AUTOSAR XML (schema 314)
package /ComponentType
  internal behavior Sa_MtrPos_InternalBehavior: component=Sa_MtrPos
    timing event MtrPos_Init1_InitEvent: start-on-event=MtrPos_Init1, period=0
    timing event TMT_MtrPos_Per2: start-on-event=MtrPos_Per2, period=0.002
    operation invoked event OIT_MtrPos_SCom_ReadEOLMtrCals_MtrPos_SCom_ReadEOLMtrCals: start-on-event=MtrPos_SCom_ReadEOLMtrCals, operation=MtrPos_SCom.ReadEOLMtrCals
    operation invoked event OIT_MtrPos_SCom_SetEOLMtrCals_MtrPos_SCom_SetEOLMtrCals: start-on-event=MtrPos_SCom_SetEOLMtrCals, operation=MtrPos_SCom.SetEOLMtrCals
    per instance memory MtrPosSnsr_EOLData: type=MtrPosCal_DataType, type-definition=/DataType/MtrPosCal_DataType
    port-api-options:
      enable-take-address=false, indirect-api=false, port=AlignedCumMtrPosMRF
      enable-take-address=false, indirect-api=false, port=AssistAssemblyPolarity
      enable-take-address=false, indirect-api=false, port=CumMtrPosCRF
      enable-take-address=false, indirect-api=false, port=CumMtrPosMRF
      enable-take-address=false, indirect-api=false, port=EOLMtrCals
      enable-take-address=false, indirect-api=false, port=MtrPos_SCom
      enable-take-address=false, indirect-api=false, port=SysCCumMtrPosCRF
      enable-take-address=false, indirect-api=false, port=SysCCumMtrPosMRF
    4 x runnable:
      MtrPos_Init1
      MtrPos_Per2
        data read access READ_AssistAssemblyPolarity_Cnt_s08: data-element=AssistAssemblyPolarity.Cnt_s08
        5 x data write access:
          WRITE_AlignedCumMtrPosMRF_Deg_f32: data-element=AlignedCumMtrPosMRF.Deg_f32
          WRITE_CumMtrPosCRF_Deg_f32: data-element=CumMtrPosCRF.Deg_f32
          WRITE_CumMtrPosMRF_Deg_f32: data-element=CumMtrPosMRF.Deg_f32
          WRITE_SysCCumMtrPosCRF_Deg_f32: data-element=SysCCumMtrPosCRF.Deg_f32
          WRITE_SysCCumMtrPosMRF_Deg_f32: data-element=SysCCumMtrPosMRF.Deg_f32
      MtrPos_SCom_ReadEOLMtrCals
      MtrPos_SCom_SetEOLMtrCals
        sync call SC_EOLMtrCals_WriteBlock: operation=EOLMtrCals.WriteBlock, timeout=0
    service-needss:
      swc nv block needs MtrPosCal_EOLData: n-data-sets=0, readonly=false, reliability=LOW, resistant-to-changed-sw=false, restore-at-start=false, write-only-once=false, writing-frequency=0, writing-priority=LOW, mirror-block=MtrPosSnsr_EOLData
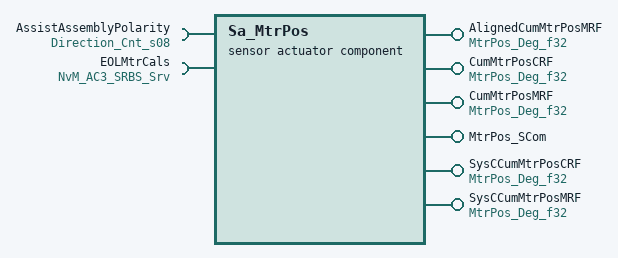
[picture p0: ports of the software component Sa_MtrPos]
  sensor actuator software component type Sa_MtrPos
    6 x provide port:
      AlignedCumMtrPosMRF: unqueued-sender-com-spec{data-element=Deg_f32, can-invalidate=false, init-value=D_ZERO_ULS_F32}, provided-interface=MtrPos_Deg_f32
      CumMtrPosCRF: unqueued-sender-com-spec{data-element=Deg_f32, can-invalidate=false, init-value=D_ZERO_ULS_F32}, provided-interface=MtrPos_Deg_f32
      CumMtrPosMRF: unqueued-sender-com-spec{data-element=Deg_f32, can-invalidate=false, init-value=D_ZERO_ULS_F32}, provided-interface=MtrPos_Deg_f32
      MtrPos_SCom: provided-com-specs=[{operation=ReadEOLMtrCals, queue-length=1}, {operation=SetEOLMtrCals, queue-length=1}], provided-interface=MtrPos_SCom
      SysCCumMtrPosCRF: unqueued-sender-com-spec{data-element=Deg_f32, can-invalidate=false, init-value=D_ZERO_ULS_F32}, provided-interface=MtrPos_Deg_f32
      SysCCumMtrPosMRF: unqueued-sender-com-spec{data-element=Deg_f32, can-invalidate=false, init-value=D_ZERO_ULS_F32}, provided-interface=MtrPos_Deg_f32
    require port AssistAssemblyPolarity: unqueued-receiver-com-spec{data-element=Cnt_s08, init-value=D_ZERO_CNT_S8}, required-interface=Direction_Cnt_s08
    require port EOLMtrCals: required-com-specs=[EraseBlock, GetErrorStatus, InvalidateNvBlock, ReadBlock, SetRamBlockStatus, WriteBlock], required-interface=NvM_AC3_SRBS_Srv
  swc implementation Sa_MtrPos_Implementation: behavior=Sa_MtrPos_InternalBehavior
    code-descriptors:
      code Code: type=SRC
